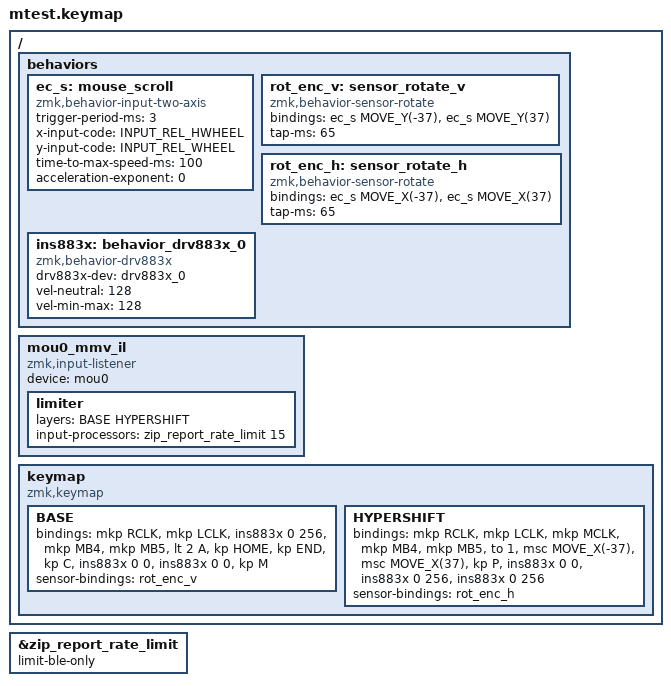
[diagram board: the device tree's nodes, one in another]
#include <behaviors.dtsi>
#include <dt-bindings/zmk/bt.h>
#include <dt-bindings/zmk/keys.h>
#include <dt-bindings/zmk/outputs.h>
#include <dt-bindings/zmk/pointing.h>

#include <input/processors/report_rate_limit.dtsi>


#define BASE 0
#define HYPERSHIFT 1


&zip_report_rate_limit {
        limit-ble-only;
};

/ {

    behaviors {
        ec_s: mouse_scroll {
            compatible = "zmk,behavior-input-two-axis";
            #binding-cells = <1>;
            trigger-period-ms = <3>;
            x-input-code = <INPUT_REL_HWHEEL>;
            y-input-code = <INPUT_REL_WHEEL>;
            time-to-max-speed-ms = <100>;
            acceleration-exponent = <0>;
        };

        rot_enc_v: sensor_rotate_v {
            compatible = "zmk,behavior-sensor-rotate";
            #sensor-binding-cells = <0>;
            bindings = <&ec_s MOVE_Y(-37)>, <&ec_s MOVE_Y(37)>;
            tap-ms = <65>;
        };

        rot_enc_h: sensor_rotate_h {
            compatible = "zmk,behavior-sensor-rotate";
            #sensor-binding-cells = <0>;
            bindings = <&ec_s MOVE_X(-37)>, <&ec_s MOVE_X(37)>;
            tap-ms = <65>;
        };
        
        ins883x: behavior_drv883x_0 {
            compatible = "zmk,behavior-drv883x";
            #binding-cells = <2>;
            drv883x-dev = <&drv883x_0>;
            vel-neutral = <128>;
            vel-min-max = <128>;
        };
    };

    mou0_mmv_il {
        compatible = "zmk,input-listener";
        device = <&mou0>;
        limiter {
                layers = <BASE HYPERSHIFT>;
                input-processors = <&zip_report_rate_limit 15>;
        };
    };

    keymap {
        compatible = "zmk,keymap";

        BASE {
            bindings = <
                &mkp RCLK
                &mkp LCLK
                &ins883x 0 256
                &mkp MB4
                &mkp MB5
                &lt 2 A
                &kp HOME
                &kp END
                &kp C
                &ins883x 0 0
                &ins883x 0 0
                &kp M
            >;
            sensor-bindings = <&rot_enc_v>;
        };

        HYPERSHIFT {
            bindings = <
                &mkp RCLK
                &mkp LCLK
                &mkp MCLK
                &mkp MB4
                &mkp MB5
                &to 1
                &msc MOVE_X(-37)
                &msc MOVE_X(37)
                &kp P
                &ins883x 0 0
                &ins883x 0 256
                &ins883x 0 256
            >;
            sensor-bindings = <&rot_enc_h>;
        };
    };
};
